# MIMXRT1064 register map
Vendor: nxp.com; File version: 1.0
CPU: CM7 r0p1, little endian, MPU, FPU, VTOR, 4 interrupt priority bits
Registers are 32-bit, read-write, reset 0x0 unless marked. A register's access mark holds for its fields unless they carry their own. Offsets are from the block's base; [hi:lo] are bit positions; {n}, {i} and the like mark numbered series; 'fields as' and 'values as' point back to an identical list.

## CCM_ANALOG
Base 0x400D8000; register names take the prefix CCM_ANALOG_
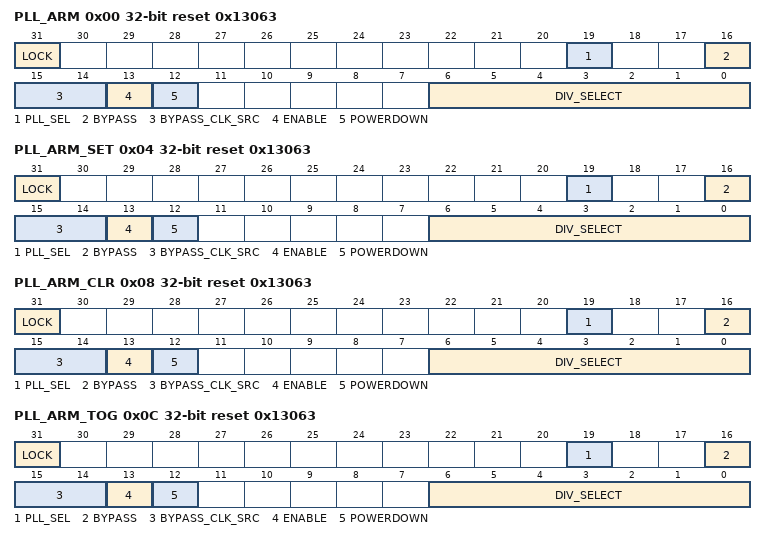
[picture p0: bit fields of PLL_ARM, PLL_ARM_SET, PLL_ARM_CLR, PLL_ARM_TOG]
0x00 PLL_ARM reset 0x13063 — Analog ARM PLL control Register
  [31] LOCK ro — 1 - PLL is currently locked. 0 - PLL is not currently locked.
  [19] PLL_SEL — Reserved
  [16] BYPASS — Bypass the PLL.
  [15:14] BYPASS_CLK_SRC — Determines the bypass source
    0=REF_CLK_24M (Select the 24MHz oscillator as source.); 1=CLK1 (Select the CLK1_N / CLK1_P as source.)
  [13] ENABLE — Enable the clock output.
  [12] POWERDOWN — Powers down the PLL.
  [6:0] DIV_SELECT — This field controls the PLL loop divider
0x04 PLL_ARM_SET reset 0x13063 — Analog ARM PLL control Register
  fields as PLL_ARM
0x08 PLL_ARM_CLR reset 0x13063 — Analog ARM PLL control Register
  fields as PLL_ARM
0x0C PLL_ARM_TOG reset 0x13063 — Analog ARM PLL control Register
  fields as PLL_ARM
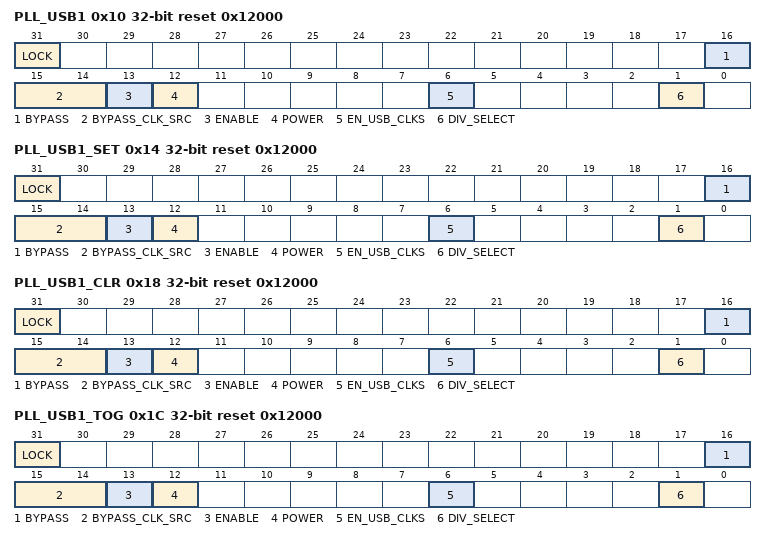
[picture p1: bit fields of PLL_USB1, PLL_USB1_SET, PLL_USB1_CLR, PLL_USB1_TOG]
0x10 PLL_USB1 reset 0x12000 — Analog USB1 480MHz PLL Control Register
  [31] LOCK ro — 1 - PLL is currently locked. 0 - PLL is not currently locked.
  [16] BYPASS — Bypass the PLL.
  [15:14] BYPASS_CLK_SRC — Determines the bypass source.
    values as PLL_ARM.BYPASS_CLK_SRC
  [13] ENABLE — Enable the PLL clock output.
  [12] POWER — Powers up the PLL. This bit will be set automatically when USBPHY0 remote wakeup event happens.
  [6] EN_USB_CLKS — Powers the 9-phase PLL outputs for USBPHYn
    0=PLL outputs for USBPHYn off; 1=PLL outputs for USBPHYn on
  [1] DIV_SELECT — This field controls the PLL loop divider. 0 - Fout=Fref*20; 1 - Fout=Fref*22.
0x14 PLL_USB1_SET reset 0x12000 — Analog USB1 480MHz PLL Control Register
  fields as PLL_USB1
0x18 PLL_USB1_CLR reset 0x12000 — Analog USB1 480MHz PLL Control Register
  fields as PLL_USB1
0x1C PLL_USB1_TOG reset 0x12000 — Analog USB1 480MHz PLL Control Register
  fields as PLL_USB1
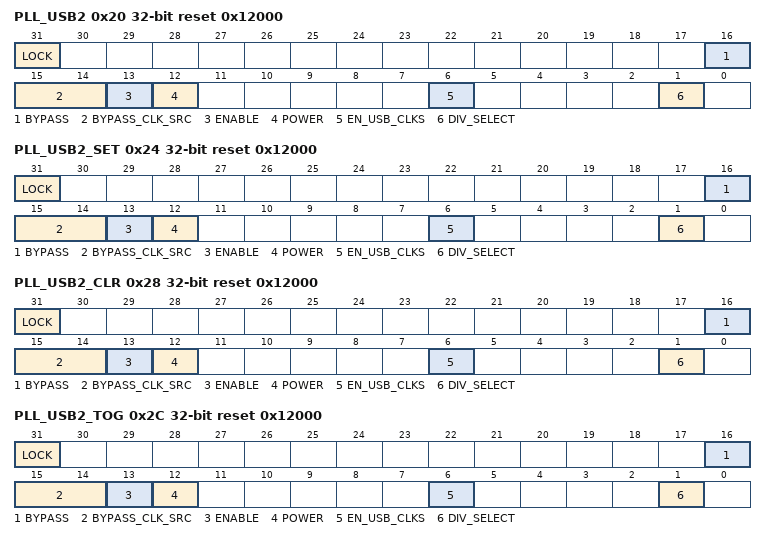
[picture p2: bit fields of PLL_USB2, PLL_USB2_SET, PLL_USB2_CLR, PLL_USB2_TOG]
0x20 PLL_USB2 reset 0x12000 — Analog USB2 480MHz PLL Control Register
  [31] LOCK ro — 1 - PLL is currently locked. 0 - PLL is not currently locked.
  [16] BYPASS — Bypass the PLL.
  [15:14] BYPASS_CLK_SRC — Determines the bypass source.
    values as PLL_ARM.BYPASS_CLK_SRC
  [13] ENABLE — Enable the PLL clock output.
  [12] POWER — Powers up the PLL. This bit will be set automatically when USBPHY1 remote wakeup event happens.
  [6] EN_USB_CLKS — 0: 8-phase PLL outputs for USBPHY1 are powered down
  [1] DIV_SELECT — This field controls the PLL loop divider. 0 - Fout=Fref*20; 1 - Fout=Fref*22.
0x24 PLL_USB2_SET reset 0x12000 — Analog USB2 480MHz PLL Control Register
  fields as PLL_USB2
0x28 PLL_USB2_CLR reset 0x12000 — Analog USB2 480MHz PLL Control Register
  fields as PLL_USB2
0x2C PLL_USB2_TOG reset 0x12000 — Analog USB2 480MHz PLL Control Register
  fields as PLL_USB2
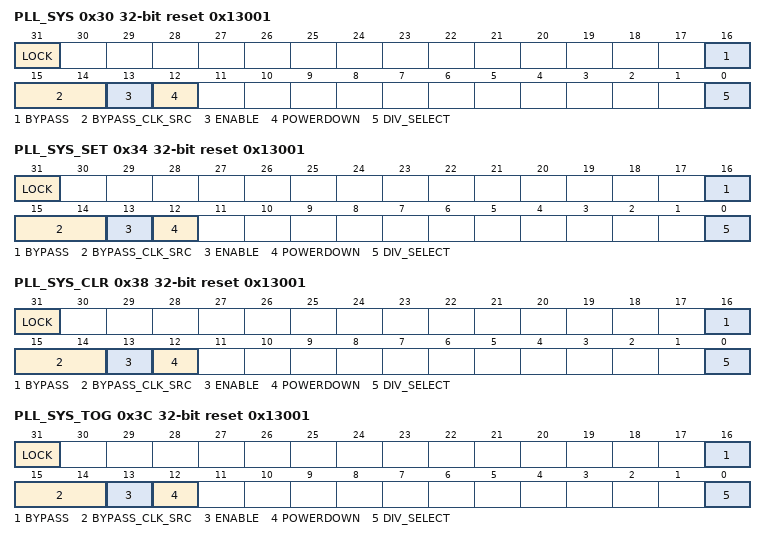
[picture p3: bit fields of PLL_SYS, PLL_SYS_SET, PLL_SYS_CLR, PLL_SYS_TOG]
0x30 PLL_SYS reset 0x13001 — Analog System PLL Control Register
  [31] LOCK ro — 1 - PLL is currently locked; 0 - PLL is not currently locked.
  [16] BYPASS — Bypass the PLL.
  [15:14] BYPASS_CLK_SRC — Determines the bypass source.
    values as PLL_ARM.BYPASS_CLK_SRC
  [13] ENABLE — Enable PLL output
  [12] POWERDOWN — Powers down the PLL.
  [0] DIV_SELECT — This field controls the PLL loop divider. 0 - Fout=Fref*20; 1 - Fout=Fref*22.
0x34 PLL_SYS_SET reset 0x13001 — Analog System PLL Control Register
  fields as PLL_SYS
0x38 PLL_SYS_CLR reset 0x13001 — Analog System PLL Control Register
  fields as PLL_SYS
0x3C PLL_SYS_TOG reset 0x13001 — Analog System PLL Control Register
  fields as PLL_SYS
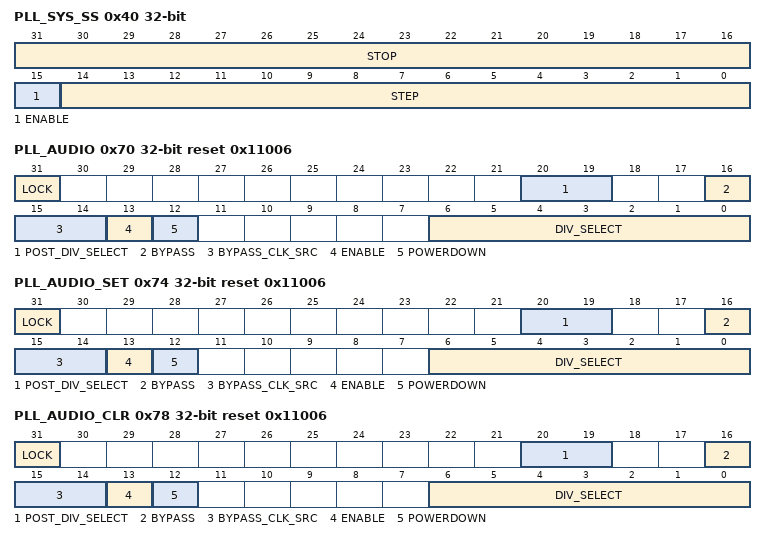
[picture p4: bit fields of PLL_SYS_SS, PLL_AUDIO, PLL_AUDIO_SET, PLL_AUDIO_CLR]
0x40 PLL_SYS_SS — 528MHz System PLL Spread Spectrum Register
  [31:16] STOP — Frequency change = stop/CCM_ANALOG_PLL_SYS_DENOM[B]*24MHz.
  [15] ENABLE — Enable bit
    0=Spread spectrum modulation disabled; 1=Soread spectrum modulation enabled
  [14:0] STEP — Frequency change step = step/CCM_ANALOG_PLL_SYS_DENOM[B]*24MHz.
0x50 PLL_SYS_NUM — Numerator of 528MHz System PLL Fractional Loop Divider Register
  [29:0] A — 30 bit numerator (A) of fractional loop divider (signed integer).
0x60 PLL_SYS_DENOM reset 0x12 — Denominator of 528MHz System PLL Fractional Loop Divider Register
  [29:0] B — 30 bit Denominator (B) of fractional loop divider (unsigned integer).
0x70 PLL_AUDIO reset 0x11006 — Analog Audio PLL control Register
  [31] LOCK ro — 1 - PLL is currently locked. 0 - PLL is not currently locked.
  [20:19] POST_DIV_SELECT — These bits implement a divider after the PLL, but before the enable and bypass mux.
    0=Divide by 4; 1=Divide by 2; 2=Divide by 1
  [16] BYPASS — Bypass the PLL.
  [15:14] BYPASS_CLK_SRC — Determines the bypass source.
    values as PLL_ARM.BYPASS_CLK_SRC
  [13] ENABLE — Enable PLL output
  [12] POWERDOWN — Powers down the PLL.
  [6:0] DIV_SELECT — This field controls the PLL loop divider. Valid range for DIV_SELECT divider value: 27~54.
0x74 PLL_AUDIO_SET reset 0x11006 — Analog Audio PLL control Register
  fields as PLL_AUDIO
0x78 PLL_AUDIO_CLR reset 0x11006 — Analog Audio PLL control Register
  fields as PLL_AUDIO
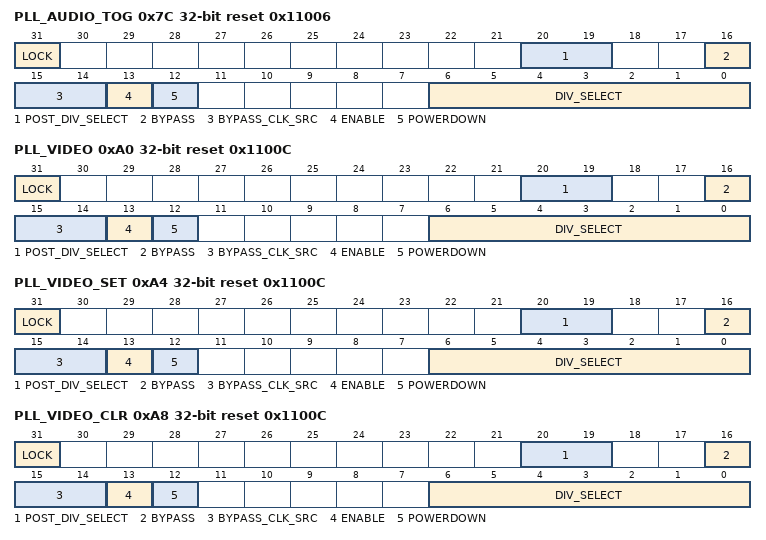
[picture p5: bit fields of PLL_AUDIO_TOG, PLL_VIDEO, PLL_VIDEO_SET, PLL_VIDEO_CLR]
0x7C PLL_AUDIO_TOG reset 0x11006 — Analog Audio PLL control Register
  fields as PLL_AUDIO
0x80 PLL_AUDIO_NUM reset 0x5F5E100 — Numerator of Audio PLL Fractional Loop Divider Register
  [29:0] A — 30 bit numerator of fractional loop divider.
0x90 PLL_AUDIO_DENOM reset 0x2964619C — Denominator of Audio PLL Fractional Loop Divider Register
  [29:0] B — 30 bit Denominator of fractional loop divider.
0xA0 PLL_VIDEO reset 0x1100C — Analog Video PLL control Register
  [31] LOCK ro — 1 - PLL is currently locked; 0 - PLL is not currently locked.
  [20:19] POST_DIV_SELECT — These bits implement a divider after the PLL, but before the enable and bypass mux.
    0=Divide by 4; 1=Divide by 2; 2=Divide by 1
  [16] BYPASS — Bypass the PLL.
  [15:14] BYPASS_CLK_SRC — Determines the bypass source.
    values as PLL_ARM.BYPASS_CLK_SRC
  [13] ENABLE — Enalbe PLL output
  [12] POWERDOWN — Powers down the PLL.
  [6:0] DIV_SELECT — This field controls the PLL loop divider. Valid range for DIV_SELECT divider value: 27~54.
0xA4 PLL_VIDEO_SET reset 0x1100C — Analog Video PLL control Register
  fields as PLL_VIDEO
0xA8 PLL_VIDEO_CLR reset 0x1100C — Analog Video PLL control Register
  fields as PLL_VIDEO
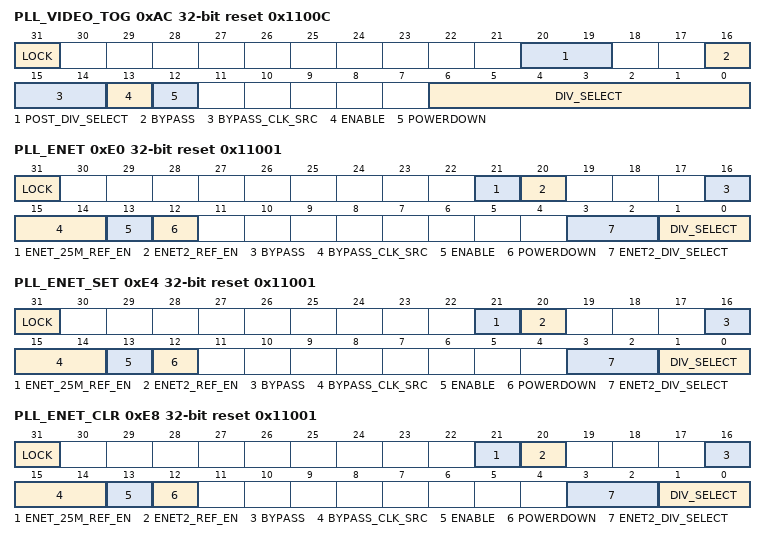
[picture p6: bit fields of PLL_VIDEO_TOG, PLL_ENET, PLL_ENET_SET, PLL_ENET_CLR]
0xAC PLL_VIDEO_TOG reset 0x1100C — Analog Video PLL control Register
  fields as PLL_VIDEO
0xB0 PLL_VIDEO_NUM reset 0x5F5E100 — Numerator of Video PLL Fractional Loop Divider Register
  [29:0] A — 30 bit numerator of fractional loop divider(Signed number), absolute value should be less than denominator
0xC0 PLL_VIDEO_DENOM reset 0x10A24447 — Denominator of Video PLL Fractional Loop Divider Register
  [29:0] B — 30 bit Denominator of fractional loop divider.
0xE0 PLL_ENET reset 0x11001 — Analog ENET PLL Control Register
  [31] LOCK ro — 1 - PLL is currently locked; 0 - PLL is not currently locked.
  [21] ENET_25M_REF_EN — Enable the PLL providing ENET 25 MHz reference clock
  [20] ENET2_REF_EN — Enable the PLL providing the ENET2 reference clock
  [16] BYPASS — Bypass the PLL.
  [15:14] BYPASS_CLK_SRC — Determines the bypass source.
    values as PLL_ARM.BYPASS_CLK_SRC
  [13] ENABLE — Enable the PLL providing the ENET reference clock.
  [12] POWERDOWN — Powers down the PLL.
  [3:2] ENET2_DIV_SELECT — Controls the frequency of the ENET2 reference clock.
    0=25MHz; 1=50MHz; 2=100MHz (not 50% duty cycle); 3=125MHz
  [1:0] DIV_SELECT — Controls the frequency of the ethernet reference clock
0xE4 PLL_ENET_SET reset 0x11001 — Analog ENET PLL Control Register
  fields as PLL_ENET
0xE8 PLL_ENET_CLR reset 0x11001 — Analog ENET PLL Control Register
  fields as PLL_ENET
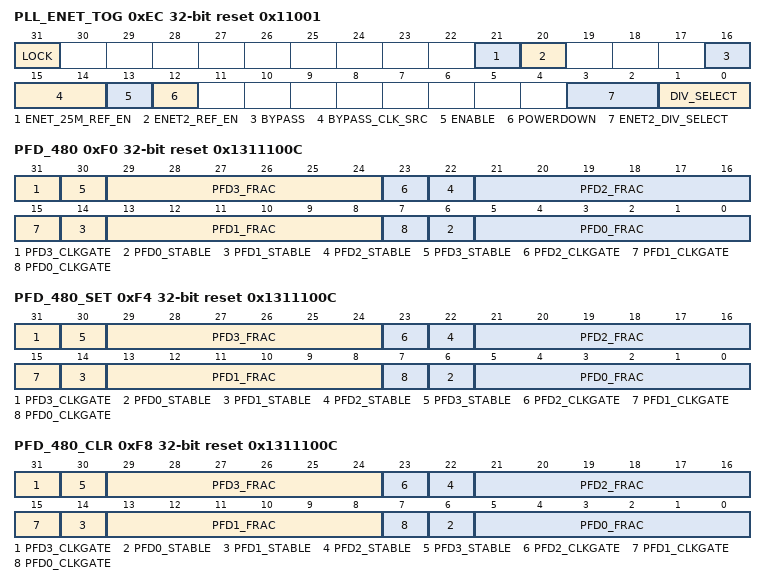
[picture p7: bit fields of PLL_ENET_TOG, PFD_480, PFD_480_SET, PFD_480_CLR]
0xEC PLL_ENET_TOG reset 0x11001 — Analog ENET PLL Control Register
  fields as PLL_ENET
0xF0 PFD_480 reset 0x1311100C — 480MHz Clock (PLL3) Phase Fractional Divider Control Register
  [31] PFD3_CLKGATE — IO Clock Gate
  [8n+6] PFD{n}_STABLE ro (n=0..3) — This read-only bitfield is for DIAGNOSTIC PURPOSES ONLY since the fractional divider should become stable quickly enough that this field will never need to be used by either device driver or application code
  [8n+5:8n] PFD{n}_FRAC (n=0..3) — This field controls the fractional divide value
  [23] PFD2_CLKGATE — IO Clock Gate
  [15] PFD1_CLKGATE — IO Clock Gate
  [7] PFD0_CLKGATE — If set to 1, the IO fractional divider clock (reference ref_pfd0) is off (power savings)
0xF4 PFD_480_SET reset 0x1311100C — 480MHz Clock (PLL3) Phase Fractional Divider Control Register
  fields as PFD_480
0xF8 PFD_480_CLR reset 0x1311100C — 480MHz Clock (PLL3) Phase Fractional Divider Control Register
  fields as PFD_480
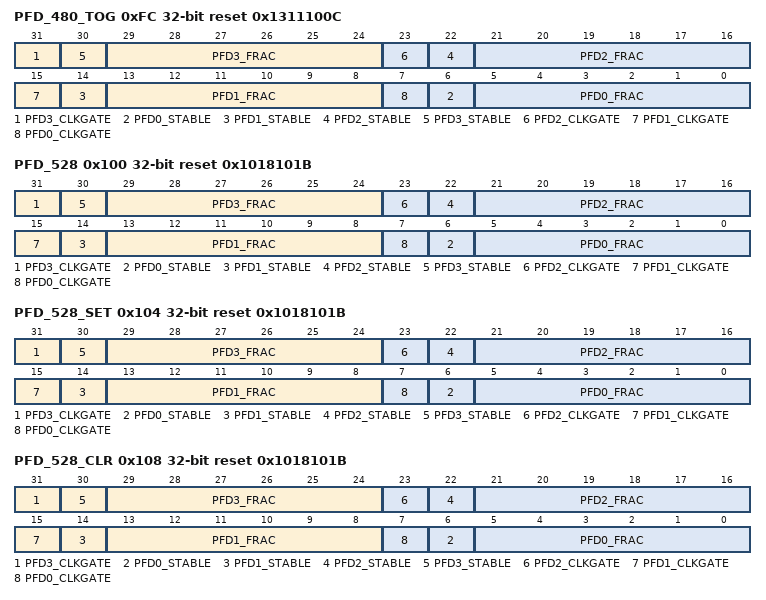
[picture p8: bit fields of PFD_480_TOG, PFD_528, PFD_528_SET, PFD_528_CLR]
0xFC PFD_480_TOG reset 0x1311100C — 480MHz Clock (PLL3) Phase Fractional Divider Control Register
  fields as PFD_480
0x100 PFD_528 reset 0x1018101B — 528MHz Clock (PLL2) Phase Fractional Divider Control Register
  fields as PFD_480
0x104 PFD_528_SET reset 0x1018101B — 528MHz Clock (PLL2) Phase Fractional Divider Control Register
  fields as PFD_480
0x108 PFD_528_CLR reset 0x1018101B — 528MHz Clock (PLL2) Phase Fractional Divider Control Register
  fields as PFD_480
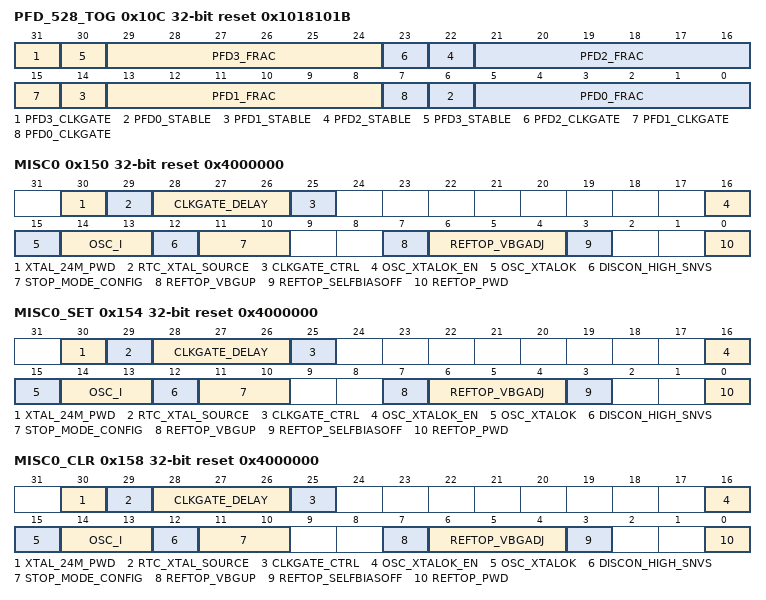
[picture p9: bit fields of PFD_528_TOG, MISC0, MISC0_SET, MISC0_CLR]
0x10C PFD_528_TOG reset 0x1018101B — 528MHz Clock (PLL2) Phase Fractional Divider Control Register
  fields as PFD_480
0x150 MISC0 reset 0x4000000 — Miscellaneous Register 0
  [30] XTAL_24M_PWD — This field powers down the 24M crystal oscillator if set true
  [29] RTC_XTAL_SOURCE — This field indicates which chip source is being used for the rtc clock
    0=Internal ring oscillator; 1=RTC_XTAL
  [28:26] CLKGATE_DELAY — This field specifies the delay between powering up the XTAL 24MHz clock and releasing the clock to the digital logic inside the analog block
    0=0.5ms; 1=1.0ms; 2=2.0ms; 3=3.0ms; 4=4.0ms; 5=5.0ms; 6=6.0ms; 7=7.0ms
  [25] CLKGATE_CTRL — This bit allows disabling the clock gate (always ungated) for the xtal 24MHz clock that clocks the digital logic in the analog block
    0=ALLOW_AUTO_GATE (Allow the logic to automatically gate the clock when the XTAL is powered down.); 1=NO_AUTO_GATE (Prevent the logic from ever gating off the clock.)
  [16] OSC_XTALOK_EN — This bit enables the detector that signals when the 24MHz crystal oscillator is stable
  [15] OSC_XTALOK ro — Status bit that signals that the output of the 24-MHz crystal oscillator is stable
  [14:13] OSC_I — This field determines the bias current in the 24MHz oscillator
    0=NOMINAL; 1=MINUS_12_5_PERCENT (Decrease current by 12.5%); 2=MINUS_25_PERCENT (Decrease current by 25.0%); 3=MINUS_37_5_PERCENT (Decrease current by 37.5%)
  [12] DISCON_HIGH_SNVS — This bit controls a switch from VDD_HIGH_IN to VDD_SNVS_IN.
    0=Turn on the switch; 1=Turn off the switch
  [11:10] STOP_MODE_CONFIG — Configure the analog behavior in stop mode.
    0=All analog except RTC powered down on stop mode assertion; 1=Beside RTC, analog bandgap, 1p1 and 2p5 regulators are also on; 2=Beside RTC, 1p1 and 2p5 regulators are also on, low-power bandgap is selected so that the normal analog bandgap together with the rest analog is powered down; 3=Beside RTC, low-power bandgap is selected and the rest analog is powered down
  [7] REFTOP_VBGUP — Status bit that signals the analog bandgap voltage is up and stable
  [6:4] REFTOP_VBGADJ — Not related to CCM. See Power Management Unit (PMU)
    0=Nominal VBG; 1=VBG+0.78%; 2=VBG+1.56%; 3=VBG+2.34%; 4=VBG-0.78%; 5=VBG-1.56%; 6=VBG-2.34%; 7=VBG-3.12%
  [3] REFTOP_SELFBIASOFF — Control bit to disable the self-bias circuit in the analog bandgap
    0=Uses coarse bias currents for startup; 1=Uses bandgap-based bias currents for best performance
  [0] REFTOP_PWD — Control bit to power-down the analog bandgap reference circuitry
0x154 MISC0_SET reset 0x4000000 — Miscellaneous Register 0
  fields as MISC0
0x158 MISC0_CLR reset 0x4000000 — Miscellaneous Register 0
  fields as MISC0
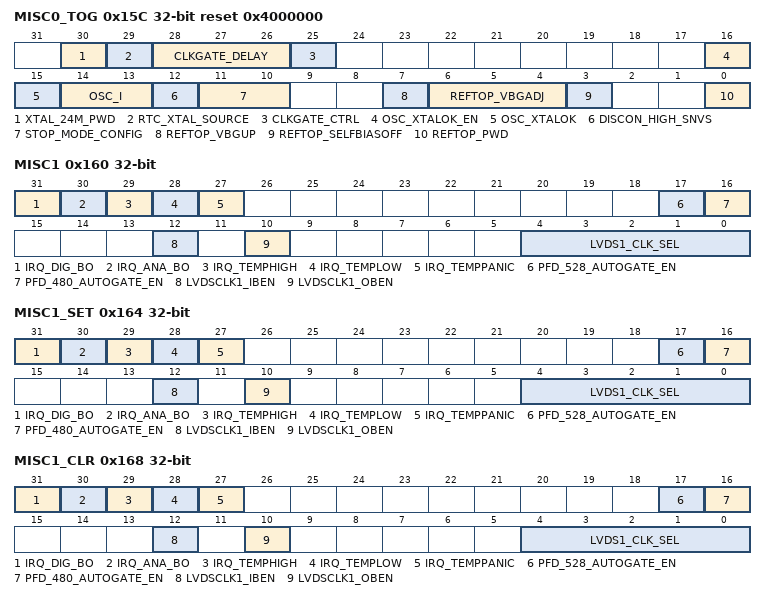
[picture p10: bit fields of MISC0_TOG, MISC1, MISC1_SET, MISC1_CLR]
0x15C MISC0_TOG reset 0x4000000 — Miscellaneous Register 0
  fields as MISC0
0x160 MISC1 — Miscellaneous Register 1
  [31] IRQ_DIG_BO write-1-clears — This status bit is set to one when when any of the digital regulator brownout interrupts assert
  [30] IRQ_ANA_BO write-1-clears — This status bit is set to one when when any of the analog regulator brownout interrupts assert
  [29] IRQ_TEMPHIGH write-1-clears — This status bit is set to one when the temperature sensor high interrupt asserts for high temperature
  [28] IRQ_TEMPLOW write-1-clears — This status bit is set to one when the temperature sensor low interrupt asserts for low temperature
  [27] IRQ_TEMPPANIC write-1-clears — This status bit is set to one when the temperature sensor panic interrupt asserts for a panic high temperature
  [17] PFD_528_AUTOGATE_EN — This enables a feature that will clkgate (reset) all PFD_528 clocks anytime the PLL_528 is unlocked or powered off
  [16] PFD_480_AUTOGATE_EN — This enables a feature that will clkgate (reset) all PFD_480 clocks anytime the USB1_PLL_480 is unlocked or powered off
  [12] LVDSCLK1_IBEN — This enables the LVDS input buffer for anaclk1/1b
  [10] LVDSCLK1_OBEN — This enables the LVDS output buffer for anaclk1/1b
  [4:0] LVDS1_CLK_SEL — This field selects the clk to be routed to anaclk1/1b.
    0=ARM_PLL; 1=SYS_PLL (System PLL); {v}=PFD{v+2} (ref_pfd{v+2}_clk == pll2_pfd{v-2}_clk) (v=2..5); 6=AUDIO_PLL; 7=VIDEO_PLL; 9=ETHERNET_REF (ethernet ref clock (ENET_PLL)); 12=USB1_PLL (USB1 PLL clock); 13=USB2_PLL (USB2 PLL clock); {v}=PFD{v-14} (ref_pfd{v-14}_clk == pll3_pfd{v-14}_clk) (v=14..17); 18=XTAL (xtal (24M))
0x164 MISC1_SET — Miscellaneous Register 1
  fields as MISC1
0x168 MISC1_CLR — Miscellaneous Register 1
  fields as MISC1
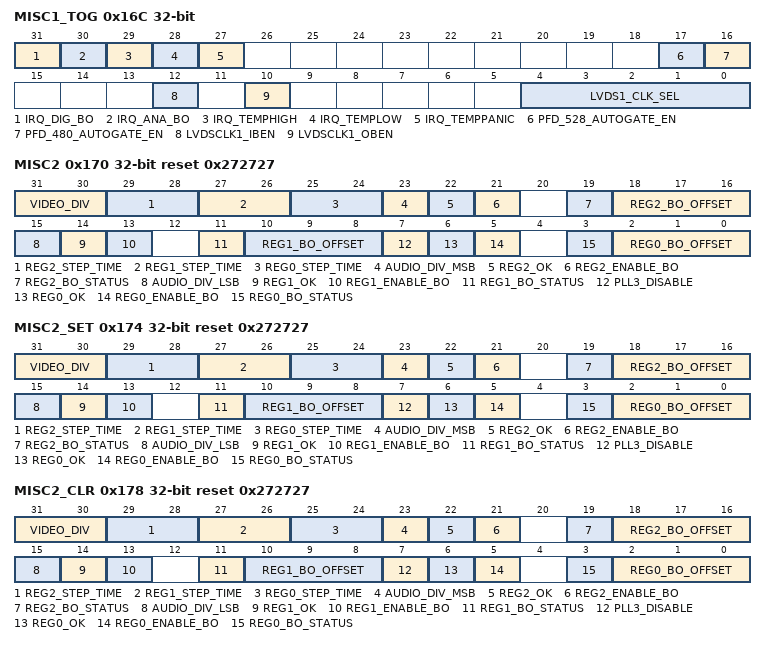
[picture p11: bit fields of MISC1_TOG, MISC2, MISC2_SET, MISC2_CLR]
0x16C MISC1_TOG — Miscellaneous Register 1
  fields as MISC1
0x170 MISC2 reset 0x272727 — Miscellaneous Register 2
  [31:30] VIDEO_DIV — Post-divider for video
    0=divide by 1 (Default); 1=divide by 2; 2=divide by 1; 3=divide by 4
  [29:28] REG2_STEP_TIME — Number of clock periods (24MHz clock).Not related to CCM. See Power Management Unit (PMU)
    0=64_CLOCKS; 1=128_CLOCKS; 2=256_CLOCKS; 3=512_CLOCKS
  [27:26] REG1_STEP_TIME — Number of clock periods (24MHz clock).Not related to CCM. See Power Management Unit (PMU)
    0=64_CLOCKS; 1=128_CLOCKS; 2=256_CLOCKS; 3=512_CLOCKS
  [25:24] REG0_STEP_TIME — Number of clock periods (24MHz clock).Not related to CCM. See Power Management Unit (PMU)
    0=64_CLOCKS; 1=128_CLOCKS; 2=256_CLOCKS; 3=512_CLOCKS
  [23] AUDIO_DIV_MSB — MSB of Post-divider for Audio PLL
    0=divide by 1 (Default); 1=divide by 2
  [22] REG2_OK ro — Signals that the voltage is above the brownout level for the SOC supply
  [21] REG2_ENABLE_BO — Enables the brownout detection.Not related to CCM. See Power Management Unit (PMU)
  [19] REG2_BO_STATUS ro — Reg2 brownout status bit.Not related to CCM. See Power Management Unit (PMU)
  [18:16] REG2_BO_OFFSET ro — This field defines the brown out voltage offset for the xPU power domain
    4=Brownout offset = 0.100V; 7=Brownout offset = 0.175V
  [15] AUDIO_DIV_LSB — LSB of Post-divider for Audio PLL
    0=divide by 1 (Default); 1=divide by 2
  [14] REG1_OK ro — GPU/VPU supply Not related to CCM. See Power Management Unit (PMU)
  [13] REG1_ENABLE_BO — Enables the brownout detection.Not related to CCM. See Power Management Unit (PMU)
  [11] REG1_BO_STATUS ro — Reg1 brownout status bit. Not related to CCM. See Power Management Unit (PMU)
    1=Brownout, supply is below target minus brownout offset
  [10:8] REG1_BO_OFFSET ro — This field defines the brown out voltage offset for the xPU power domain
    4=Brownout offset = 0.100V; 7=Brownout offset = 0.175V
  [7] PLL3_DISABLE — When USB is in low power suspend mode this Control bit is used to indicate if other system peripherals require the USB PLL3 clock when the SoC is not in low power mode
    0=PLL3 is being used by peripherals and is enabled when SoC is not in any low power mode; 1=PLL3 can be disabled when the SoC is not in any low power mode
  [6] REG0_OK ro — ARM supply Not related to CCM. See Power Management Unit (PMU)
  [5] REG0_ENABLE_BO — Enables the brownout detection.Not related to CCM. See Power Management Unit (PMU)
  [3] REG0_BO_STATUS ro — Reg0 brownout status bit.Not related to CCM. See Power Management Unit (PMU)
    1=Brownout, supply is below target minus brownout offset
  [2:0] REG0_BO_OFFSET ro — This field defines the brown out voltage offset for the CORE power domain
    4=Brownout offset = 0.100V; 7=Brownout offset = 0.175V
0x174 MISC2_SET reset 0x272727 — Miscellaneous Register 2
  fields as MISC2
0x178 MISC2_CLR reset 0x272727 — Miscellaneous Register 2
  fields as MISC2
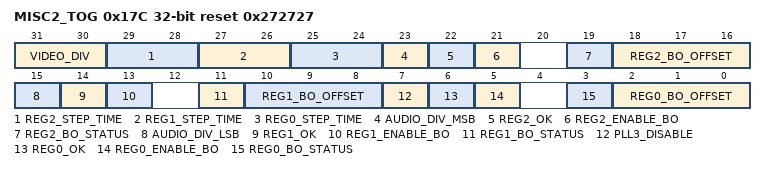
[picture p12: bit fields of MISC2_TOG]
0x17C MISC2_TOG reset 0x272727 — Miscellaneous Register 2
  fields as MISC2
